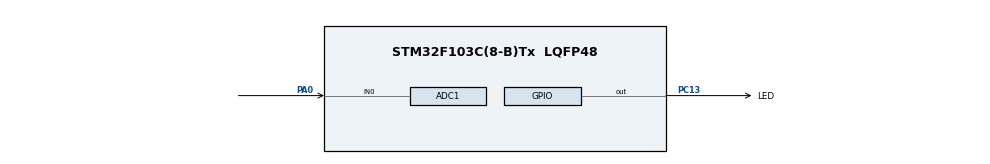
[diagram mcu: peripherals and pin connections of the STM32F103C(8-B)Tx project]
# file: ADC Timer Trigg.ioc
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ADC1.Channel-0\#ChannelRegularConversion=ADC_CHANNEL_0
ADC1.ExternalTrigConv=ADC_EXTERNALTRIGCONV_T3_TRGO
ADC1.NbrOfConversionFlag=1
ADC1.Rank-0\#ChannelRegularConversion=1
ADC1.SamplingTime-0\#ChannelRegularConversion=ADC_SAMPLETIME_28CYCLES_5
ADC1.master=1
Mcu.Family=STM32F1
Mcu.Name=STM32F103C(8-B)Tx
Mcu.Package=LQFP48
NVIC.ADC1_2_IRQn=true\:0\:0\:false\:false\:true\:true\:true
NVIC.PriorityGroup=NVIC_PRIORITYGROUP_4
PA0-WKUP.Signal=ADCx_IN0
PA13.Mode=Serial_Wire
PA13.Signal=SYS_JTMS-SWDIO
PA14.Mode=Serial_Wire
PA14.Signal=SYS_JTCK-SWCLK
PC13-TAMPER-RTC.GPIO_Label=LED
PC13-TAMPER-RTC.Signal=GPIO_Output
PD0-OSC_IN.Mode=HSE-External-Oscillator
PD0-OSC_IN.Signal=RCC_OSC_IN
PD1-OSC_OUT.Mode=HSE-External-Oscillator
PD1-OSC_OUT.Signal=RCC_OSC_OUT
ProjectManager.HeapSize=0x200
ProjectManager.StackSize=0x400
ProjectManager.TargetToolchain=STM32CubeIDE
RCC.APB1Freq_Value=8000000
RCC.APB2Freq_Value=8000000
SH.ADCx_IN0.0=ADC1_IN0,IN0
TIM3.Period=100
TIM3.Prescaler=8000
TIM3.TIM_MasterOutputTrigger=TIM_TRGO_UPDATE
VP_TIM3_VS_ClockSourceINT.Mode=Internal
board=custom

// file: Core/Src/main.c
/* USER CODE BEGIN Header */
/**
  ******************************************************************************
  * @file           : main.c
  * @brief          : Main program body
  ******************************************************************************
  * @attention
  *
  * <h2><center>&copy; Copyright (c) 2020 STMicroelectronics.
  * All rights reserved.</center></h2>
  *
  * This software component is licensed by ST under BSD 3-Clause license,
  * the "License"; You may not use this file except in compliance with the
  * License. You may obtain a copy of the License at:
  *                        opensource.org/licenses/BSD-3-Clause
  *
  ******************************************************************************
  */
/* USER CODE END Header */

#include "main.h"
#include "adc.h"
#include "tim.h"
#include "gpio.h"

void SystemClock_Config(void);

/* USER CODE BEGIN 0 */
uint32_t adcValue;
/* USER CODE END 0 */

int main(void)
{

  /* MCU Configuration--------------------------------------------------------*/

  /* Reset of all peripherals, Initializes the Flash interface and the Systick. */
  HAL_Init();

  /* Configure the system clock */
  SystemClock_Config();

  /* Initialize all configured peripherals */
  MX_GPIO_Init();
  MX_ADC1_Init();
  MX_TIM3_Init();
  /* USER CODE BEGIN 2 */
  HAL_TIM_Base_Start(&htim3);
  HAL_ADC_Start_IT(&hadc1);
  /* USER CODE END 3 */
}

void SystemClock_Config(void)
{
  RCC_OscInitTypeDef RCC_OscInitStruct = {0};
  RCC_ClkInitTypeDef RCC_ClkInitStruct = {0};
  RCC_PeriphCLKInitTypeDef PeriphClkInit = {0};

  /** Initializes the CPU, AHB and APB busses clocks
  */
  RCC_OscInitStruct.OscillatorType = RCC_OSCILLATORTYPE_HSI;
  RCC_OscInitStruct.HSIState = RCC_HSI_ON;
  RCC_OscInitStruct.HSICalibrationValue = RCC_HSICALIBRATION_DEFAULT;
  RCC_OscInitStruct.PLL.PLLState = RCC_PLL_NONE;
  if (HAL_RCC_OscConfig(&RCC_OscInitStruct) != HAL_OK)
  {
    Error_Handler();
  }
  /** Initializes the CPU, AHB and APB busses clocks
  */
  RCC_ClkInitStruct.ClockType = RCC_CLOCKTYPE_HCLK|RCC_CLOCKTYPE_SYSCLK
                              |RCC_CLOCKTYPE_PCLK1|RCC_CLOCKTYPE_PCLK2;
  RCC_ClkInitStruct.SYSCLKSource = RCC_SYSCLKSOURCE_HSI;
  RCC_ClkInitStruct.AHBCLKDivider = RCC_SYSCLK_DIV1;
  RCC_ClkInitStruct.APB1CLKDivider = RCC_HCLK_DIV1;
  RCC_ClkInitStruct.APB2CLKDivider = RCC_HCLK_DIV1;

  if (HAL_RCC_ClockConfig(&RCC_ClkInitStruct, FLASH_LATENCY_0) != HAL_OK)
  {
    Error_Handler();
  }
  PeriphClkInit.PeriphClockSelection = RCC_PERIPHCLK_ADC;
  PeriphClkInit.AdcClockSelection = RCC_ADCPCLK2_DIV2;
  if (HAL_RCCEx_PeriphCLKConfig(&PeriphClkInit) != HAL_OK)
  {
    Error_Handler();
  }
}

/* USER CODE BEGIN 4 */
void HAL_ADC_ConvCpltCallback(ADC_HandleTypeDef* hadc)
{
  /* Prevent unused argument(s) compilation warning */
  UNUSED(hadc);
  /* NOTE : This function should not be modified. When the callback is needed,
            function HAL_ADC_ConvCpltCallback must be implemented in the user file.
   */
  adcValue = HAL_ADC_GetValue(&hadc1);
  HAL_GPIO_TogglePin(LED_GPIO_Port, LED_Pin);

}
/* USER CODE END 4 */

void Error_Handler(void)
{
}

/************************ (C) COPYRIGHT STMicroelectronics *****END OF FILE****/
